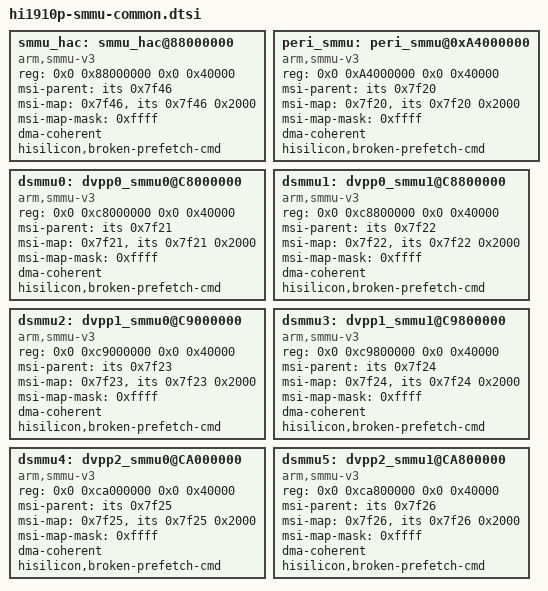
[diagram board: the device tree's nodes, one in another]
/**
* dts file for Hisilicon Ascend Dxxx Development Board
*
* Copyright (C) 2020 Hisilicon Ltd.
*
* This program is free software; you can redistribute it and/or modify
* it under the terms of the GNU General Public License version 2 as
* publishhed by the Free Software Foundation.
*
* Owner：OS
* Author:  c00283067
* Create: Tue Apr 21 20:07:41 EDT 2020
*/
    smmu_hac: smmu_hac@88000000 {
	compatible = "arm,smmu-v3";
	reg = <0x0 0x88000000 0x0 0x40000>;
	#iommu-cells = <0x1>;
	msi-parent = <&its 0x7f46>;
	msi-map = <0x7f46 &its 0x7f46 0x2000>;
	msi-map-mask = <0xffff>;
	dma-coherent;
	hisilicon,broken-prefetch-cmd;
    };

    peri_smmu: peri_smmu@0xA4000000 {
        compatible = "arm,smmu-v3";
        reg = <0x0 0xA4000000 0x0 0x40000>;
        #iommu-cells = <0x1>;
        msi-parent = <&its 0x7f20>;
        msi-map = <0x7f20 &its 0x7f20 0x2000>;
        msi-map-mask = <0xffff>;
        dma-coherent;
        hisilicon,broken-prefetch-cmd;
    };

    dsmmu0: dvpp0_smmu0@C8000000 {
        compatible = "arm,smmu-v3";
        reg = <0x0 0xc8000000 0x0 0x40000>;
        #iommu-cells = <1>;
        msi-parent = <&its 0x7f21>;
        msi-map = <0x7f21 &its 0x7f21 0x2000>;
        msi-map-mask = <0xffff>;
        dma-coherent;
        hisilicon,broken-prefetch-cmd;
    };

    dsmmu1: dvpp0_smmu1@C8800000 {
        compatible = "arm,smmu-v3";
        reg = <0x0 0xc8800000 0x0 0x40000>;
        #iommu-cells = <1>;
        msi-parent = <&its 0x7f22>;
        msi-map = <0x7f22 &its 0x7f22 0x2000>;
        msi-map-mask = <0xffff>;
        dma-coherent;
        hisilicon,broken-prefetch-cmd;
    };

    dsmmu2: dvpp1_smmu0@C9000000 {
        compatible = "arm,smmu-v3";
        reg = <0x0 0xc9000000 0x0 0x40000>;
        #iommu-cells = <1>;
        msi-parent = <&its 0x7f23>;
        msi-map = <0x7f23 &its 0x7f23 0x2000>;
        msi-map-mask = <0xffff>;
        dma-coherent;
        hisilicon,broken-prefetch-cmd;
    };

    dsmmu3: dvpp1_smmu1@C9800000 {
        compatible = "arm,smmu-v3";
        reg = <0x0 0xc9800000 0x0 0x40000>;
        #iommu-cells = <1>;
        msi-parent = <&its 0x7f24>;
        msi-map = <0x7f24 &its 0x7f24 0x2000>;
        msi-map-mask = <0xffff>;
        dma-coherent;
        hisilicon,broken-prefetch-cmd;
    };

    dsmmu4: dvpp2_smmu0@CA000000 {
        compatible = "arm,smmu-v3";
        reg = <0x0 0xca000000 0x0 0x40000>;
        #iommu-cells = <1>;
        msi-parent = <&its 0x7f25>;
        msi-map = <0x7f25 &its 0x7f25 0x2000>;
        msi-map-mask = <0xffff>;
        dma-coherent;
        hisilicon,broken-prefetch-cmd;
    };

    dsmmu5: dvpp2_smmu1@CA800000 {
        compatible = "arm,smmu-v3";
        reg = <0x0 0xca800000 0x0 0x40000>;
        #iommu-cells = <1>;
        msi-parent = <&its 0x7f26>;
        msi-map = <0x7f26 &its 0x7f26 0x2000>;
        msi-map-mask = <0xffff>;
        dma-coherent;
        hisilicon,broken-prefetch-cmd;
    };
